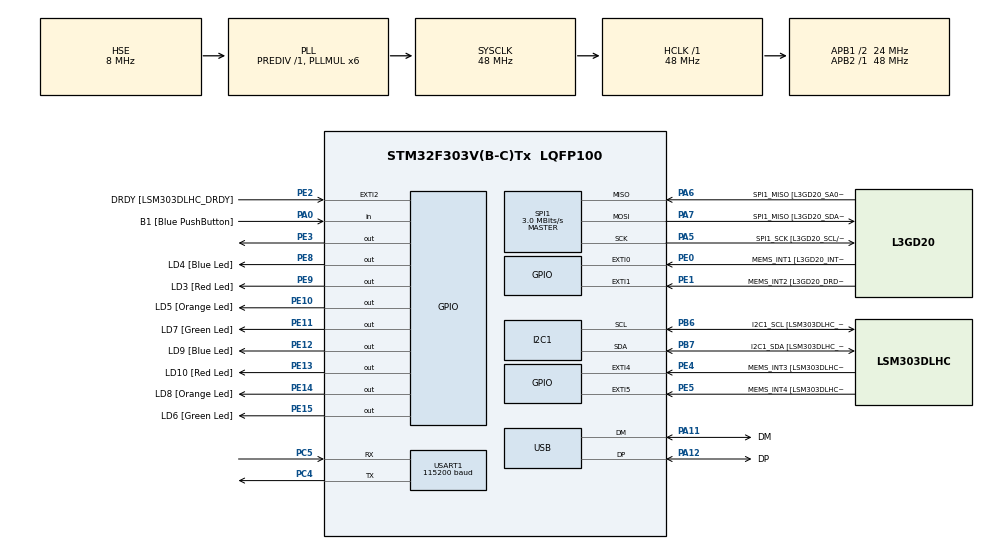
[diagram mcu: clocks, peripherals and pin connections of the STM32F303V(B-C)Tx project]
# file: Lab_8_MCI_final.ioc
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I2C1.Timing=0x2000090E
I2C1.Timing-I2C=0x2000090E
Mcu.Family=STM32F3
Mcu.Name=STM32F303V(B-C)Tx
Mcu.Package=LQFP100
NVIC.PriorityGroup=NVIC_PRIORITYGROUP_0
NVIC.SPI1_IRQn=true\:0\:0\:false\:false\:true\:true\:true\:true
PA0.GPIO_Label=B1 [Blue PushButton]
PA0.Signal=GPIO_Input
PA11.GPIO_Label=DM
PA11.Mode=Device
PA11.Signal=USB_DM
PA12.GPIO_Label=DP
PA12.Mode=Device
PA12.Signal=USB_DP
PA13.GPIO_Label=SWDIO
PA13.Mode=Serial_Wire
PA13.Signal=SYS_JTMS-SWDIO
PA14.GPIO_Label=SWCLK
PA14.Mode=Serial_Wire
PA14.Signal=SYS_JTCK-SWCLK
PA5.GPIO_Label=SPI1_SCK [L3GD20_SCL/SPC]
PA5.Mode=Full_Duplex_Master
PA5.Signal=SPI1_SCK
PA6.GPIO_Label=SPI1_MISO [L3GD20_SA0/SDO]
PA6.Mode=Full_Duplex_Master
PA6.Signal=SPI1_MISO
PA7.GPIO_Label=SPI1_MISO [L3GD20_SDA/SDI/SDO]
PA7.Mode=Full_Duplex_Master
PA7.Signal=SPI1_MOSI
PB3.GPIO_Label=SWO
PB3.Signal=SYS_JTDO-TRACESWO
PB6.GPIO_Label=I2C1_SCL [LSM303DLHC_SCL]
PB6.GPIO_Pu=GPIO_PULLUP
PB6.Mode=I2C
PB6.Signal=I2C1_SCL
PB7.GPIO_Label=I2C1_SDA [LSM303DLHC_SDA]
PB7.GPIO_Pu=GPIO_PULLUP
PB7.Mode=I2C
PB7.Signal=I2C1_SDA
PC14-OSC32_IN.GPIO_Label=OSC32_IN
PC14-OSC32_IN.Signal=RCC_OSC32_IN
PC15-OSC32_OUT.GPIO_Label=OSC32_OUT
PC15-OSC32_OUT.Signal=RCC_OSC32_OUT
PC4.Mode=Asynchronous
PC4.Signal=USART1_TX
PC5.Mode=Asynchronous
PC5.Signal=USART1_RX
PE0.GPIO_Label=MEMS_INT1 [L3GD20_INT1]
PE0.GPIO_ModeDefaultEXTI=GPIO_MODE_EVT_RISING
PE0.Signal=GPXTI0
PE1.GPIO_Label=MEMS_INT2 [L3GD20_DRDY/INT2]
PE1.GPIO_ModeDefaultEXTI=GPIO_MODE_EVT_RISING
PE1.Signal=GPXTI1
PE10.GPIO_Label=LD5 [Orange Led]
PE10.Signal=GPIO_Output
PE11.GPIO_Label=LD7 [Green Led]
PE11.Signal=GPIO_Output
PE12.GPIO_Label=LD9 [Blue Led]
PE12.Signal=GPIO_Output
PE13.GPIO_Label=LD10 [Red Led]
PE13.Signal=GPIO_Output
PE14.GPIO_Label=LD8 [Orange Led]
PE14.Signal=GPIO_Output
PE15.GPIO_Label=LD6 [Green Led]
PE15.Signal=GPIO_Output
PE2.GPIO_Label=DRDY [LSM303DLHC_DRDY]
PE2.GPIO_ModeDefaultEXTI=GPIO_MODE_EVT_RISING
PE2.Signal=GPXTI2
PE3.Signal=GPIO_Output
PE4.GPIO_Label=MEMS_INT3 [LSM303DLHC_INT1]
PE4.GPIO_ModeDefaultEXTI=GPIO_MODE_EVT_RISING
PE4.Signal=GPXTI4
PE5.GPIO_Label=MEMS_INT4 [LSM303DLHC_INT2]
PE5.GPIO_ModeDefaultEXTI=GPIO_MODE_EVT_RISING
PE5.Signal=GPXTI5
PE8.GPIO_Label=LD4 [Blue Led]
PE8.Signal=GPIO_Output
PE9.GPIO_Label=LD3 [Red Led]
PE9.Signal=GPIO_Output
PF0-OSC_IN.GPIO_Label=OSC_IN
PF0-OSC_IN.Mode=HSE-External-Clock-Source
PF0-OSC_IN.Signal=RCC_OSC_IN
PF1-OSC_OUT.GPIO_Label=OSC_OUT
PF1-OSC_OUT.Signal=RCC_OSC_OUT
ProjectManager.HeapSize=0x200
ProjectManager.StackSize=0x400
ProjectManager.TargetToolchain=CMake
RCC.AHBFreq_Value=48000000
RCC.APB1CLKDivider=RCC_HCLK_DIV2
RCC.APB1Freq_Value=24000000
RCC.APB1TimFreq_Value=48000000
RCC.APB2Freq_Value=48000000
RCC.APB2TimFreq_Value=48000000
RCC.CortexFreq_Value=48000000
RCC.HCLKFreq_Value=48000000
RCC.HSE_VALUE=8000000
RCC.HSI_VALUE=8000000
RCC.LSE_VALUE=32768
RCC.PLLMUL=RCC_PLL_MUL6
RCC.SYSCLKFreq_VALUE=48000000
RCC.SYSCLKSourceVirtual=RCC_SYSCLKSOURCE_PLLCLK
RCC.USBFreq_Value=48000000
SPI1.BaudRatePrescaler=SPI_BAUDRATEPRESCALER_16
SPI1.BaudRatePrescaler-Full_Duplex_Master=SPI_BAUDRATEPRESCALER_2
SPI1.CLKPhase=SPI_PHASE_2EDGE
SPI1.CLKPolarity=SPI_POLARITY_HIGH
SPI1.CalculateBaudRate=3.0 MBits/s
SPI1.CalculateBaudRate-Full_Duplex_Master=24.0 MBits/s
SPI1.DataSize=SPI_DATASIZE_8BIT
SPI1.Direction=SPI_DIRECTION_2LINES
SPI1.Mode=SPI_MODE_MASTER
SPI1.Mode-Full_Duplex_Master=SPI_MODE_MASTER
SPI1.VirtualType=VM_MASTER
USART1.BaudRate=115200
USART1.VirtualMode-Asynchronous=VM_ASYNC
board=STM32F3DISCOVERY

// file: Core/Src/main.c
/* USER CODE BEGIN Header */
/**
  ******************************************************************************
  * @file           : main.c
  * @brief          : Main program body
  ******************************************************************************
  * @attention
  *
  * Copyright (c) 2025 STMicroelectronics.
  * All rights reserved.
  *
  * This software is licensed under terms that can be found in the LICENSE file
  * in the root directory of this software component.
  * If no LICENSE file comes with this software, it is provided AS-IS.
  *
  ******************************************************************************
  */
/* USER CODE END Header */
#include "main.h"
#include <stdio.h>
#include <string.h>

#define CTRL_REG1      0x20
#define CTRL_REG1_VAL  0x0F  // PD=1, Xen=1, Yen=1, Zen=1 (power on + axes enabled)
#define OUT_TEMP       0x26
#define SPI_READ_CMD   0x80
#define WHO_AM_I       0x0F

#define OUT_X_L        0x28
#define OUT_X_H        0x29
#define OUT_Y_L        0x2A
#define OUT_Y_H        0x2B
#define OUT_Z_L        0x2C
#define OUT_Z_H        0x2D

I2C_HandleTypeDef hi2c1;

SPI_HandleTypeDef hspi1;

UART_HandleTypeDef huart1;

PCD_HandleTypeDef hpcd_USB_FS;

void SystemClock_Config(void);
static void MX_GPIO_Init(void);
static void MX_I2C1_Init(void);
static void MX_SPI1_Init(void);
static void MX_USART1_UART_Init(void);
static void MX_USB_PCD_Init(void);

volatile uint8_t spi_tx_in_progress = 0;
uint8_t tx_cmd;            // volatile because used in ISR sequence
uint8_t rx_val;            // volatile because written in ISR
int8_t latest_temp = 0;    // latest signed temp value
uint8_t temp_ready = 0;    // ISR -> main flag
char uart_buf[64];

#define CS_LOW()  HAL_GPIO_WritePin(GPIOE, GPIO_PIN_3, GPIO_PIN_RESET)
#define CS_HIGH() HAL_GPIO_WritePin(GPIOE, GPIO_PIN_3, GPIO_PIN_SET)
void gyro_init(void);
void start_temp_read_it(void);
#define GYRO_CS_GPIO_PORT  GPIOE
#define GYRO_CS_PIN        GPIO_PIN_3

static inline uint8_t gyro_read_cmd(uint8_t reg) {
    return (uint8_t)(0x80 | (reg & 0x3F)); // Read bit =1 ; auto-inc disabled for single
}

uint8_t read_who_am_i(void)
{
    uint8_t cmd = gyro_read_cmd(WHO_AM_I);
    uint8_t tx[2] = { cmd, 0x00 };
    uint8_t rx[2] = {0};

    HAL_GPIO_WritePin(GYRO_CS_GPIO_PORT, GYRO_CS_PIN, GPIO_PIN_RESET);
    HAL_SPI_TransmitReceive(&hspi1, tx, rx, 2, HAL_MAX_DELAY);
    HAL_GPIO_WritePin(GYRO_CS_GPIO_PORT, GYRO_CS_PIN, GPIO_PIN_SET);

    return rx[1]; // rx[0] is dummy for command, rx[1] is register value
}
static uint8_t read_who_am_i_polling(void)
{
    uint8_t cmd = gyro_read_cmd(WHO_AM_I);   // sets read bit
    uint8_t tx[2] = { cmd, 0x00 };
    uint8_t rx[2] = { 0 };

    /* CS low, transfer 2 bytes: send cmd, read reply */
    HAL_GPIO_WritePin(GYRO_CS_GPIO_PORT, GYRO_CS_PIN, GPIO_PIN_RESET);
    HAL_SPI_TransmitReceive(&hspi1, tx, rx, 2, HAL_MAX_DELAY);
    HAL_GPIO_WritePin(GYRO_CS_GPIO_PORT, GYRO_CS_PIN, GPIO_PIN_SET);

    return rx[1]; /* second byte is register value */
}
static inline uint8_t gyro_read_cmd_ai(uint8_t reg) {
    return (uint8_t)(0xC0 | (reg & 0x3F)); // 1<<7 (read) + 1<<6 (auto-increment)
}
/* Task 3: Read X,Y,Z using polling mode, convert to dps and print CSV */
void read_angular_rates_and_print(void)
{
    // Use auto-increment read of 6 bytes starting at OUT_X_L
    uint8_t cmd = gyro_read_cmd_ai(OUT_X_L);
    uint8_t tx[7]; // 1 cmd + 6 dummy
    uint8_t rx[7];
    memset(tx, 0, sizeof(tx));
    tx[0] = cmd;

    HAL_GPIO_WritePin(GYRO_CS_GPIO_PORT, GYRO_CS_PIN, GPIO_PIN_RESET);
    HAL_SPI_TransmitReceive(&hspi1, tx, rx, 7, HAL_MAX_DELAY);
    HAL_GPIO_WritePin(GYRO_CS_GPIO_PORT, GYRO_CS_PIN, GPIO_PIN_SET);

    // rx[1]..rx[6] are data (L then H per axis)
    int16_t x_raw = (int16_t)((rx[2] << 8) | rx[1]);
    int16_t y_raw = (int16_t)((rx[4] << 8) | rx[3]);
    int16_t z_raw = (int16_t)((rx[6] << 8) | rx[5]);

    float sensitivity = 0.00875f; // 8.75 mdps per LSB -> 0.00875 dps/LSB (±245 dps)
    float x_dps = x_raw * sensitivity;
    float y_dps = y_raw * sensitivity;
    float z_dps = z_raw * sensitivity;

    // Also read temperature in polling style (single byte)
    uint8_t cmdt = gyro_read_cmd(OUT_TEMP);
    uint8_t txt[2] = { cmdt, 0x00 };
    uint8_t rxt[2];
    HAL_GPIO_WritePin(GYRO_CS_GPIO_PORT, GYRO_CS_PIN, GPIO_PIN_RESET);
    HAL_SPI_TransmitReceive(&hspi1, txt, rxt, 2, HAL_MAX_DELAY);
    HAL_GPIO_WritePin(GYRO_CS_GPIO_PORT, GYRO_CS_PIN, GPIO_PIN_SET);
    int8_t temp = (int8_t)rxt[1];

    // Format: <temp>, <x_dps>, <y_dps>, <z_dps>\n
    char out[128];
    int len = snprintf(out, sizeof(out), "%d, %.2f, %.2f, %.2f\r\n", temp, x_dps, y_dps, z_dps);
    HAL_UART_Transmit(&huart1, (uint8_t*)out, len, HAL_MAX_DELAY);
}
/* helpers needed by Task 3 -------------------------------------------------*/

/* sensitivity (dps per LSB) for ±245 dps full-scale */
static const float GYRO_SENSITIVITY_DPS_PER_LSB = 0.00875f;

/* Blocking helper: read a 16-bit little-endian register pair starting at low_addr.
   Returns signed 16-bit value (OUT_L then OUT_H). */
static int16_t read_register_16(uint8_t low_addr)
{
    uint8_t cmd = gyro_read_cmd_ai(low_addr); // read + auto-inc
    uint8_t tx[7]; // will only send 1 cmd + receive 6 bytes when reading 3 axes,
                   // but for a single 16-bit read we use 1 cmd + 2 dummy
    uint8_t rx[3];
    memset(tx, 0, sizeof(tx));
    tx[0] = cmd;

    HAL_GPIO_WritePin(GYRO_CS_GPIO_PORT, GYRO_CS_PIN, GPIO_PIN_RESET);
    /* send command (1 byte) and receive 2 bytes */
    HAL_SPI_TransmitReceive(&hspi1, tx, rx, 3, HAL_MAX_DELAY);
    HAL_GPIO_WritePin(GYRO_CS_GPIO_PORT, GYRO_CS_PIN, GPIO_PIN_SET);

    /* rx[1] is first returned byte (LOW), rx[2] is HIGH if using 3-byte transfer */
    /* When using HAL_SPI_TransmitReceive with length=3: rx[0] is dummy, rx[1]=LOW, rx[2]=HIGH */
    int16_t val = (int16_t)((rx[2] << 8) | rx[1]);
    return val;
}

/* Blocking helper: read single 8-bit OUT_TEMP (signed) */
static int8_t read_temp(void)
{
    uint8_t cmd = gyro_read_cmd(OUT_TEMP);
    uint8_t tx[2] = { cmd, 0x00 };
    uint8_t rx[2] = {0};

    HAL_GPIO_WritePin(GYRO_CS_GPIO_PORT, GYRO_CS_PIN, GPIO_PIN_RESET);
    HAL_SPI_TransmitReceive(&hspi1, tx, rx, 2, HAL_MAX_DELAY);
    HAL_GPIO_WritePin(GYRO_CS_GPIO_PORT, GYRO_CS_PIN, GPIO_PIN_SET);

    return (int8_t)rx[1];
}

int main(void)
{

  /* MCU Configuration--------------------------------------------------------*/

  /* Reset of all peripherals, Initializes the Flash interface and the Systick. */
  HAL_Init();

  /* Configure the system clock */
  SystemClock_Config();

  /* Initialize all configured peripherals */
  MX_GPIO_Init();
  MX_I2C1_Init();
  MX_SPI1_Init();
  MX_USART1_UART_Init();
  MX_USB_PCD_Init();

  HAL_GPIO_WritePin(GYRO_CS_GPIO_PORT, GYRO_CS_PIN, GPIO_PIN_SET);
  gyro_init();
  // TASK 1: read WHO_AM_I and print once
    uint8_t id = read_who_am_i();
    char buf[64];
    int l = snprintf(buf, sizeof(buf), "WHO_AM_I = 0x%02X\r\n", id);
    HAL_UART_Transmit(&huart1, (uint8_t*)buf, l, HAL_MAX_DELAY);
    HAL_Delay(100);
  /* USER CODE BEGIN 2 */
const uint32_t sample_period_ms = 20; // 20 ms -> 50 Hz. Change to 100 for 10 Hz, etc.
  /* USER CODE END 2 */

  /* Infinite loop */
  /* USER CODE BEGIN WHILE */
 while (1)
{
    uint32_t ts = HAL_GetTick(); // ms timestamp

    // Read X/Y/Z in blocking mode
    int16_t x_raw = read_register_16(OUT_X_L);
    int16_t y_raw = read_register_16(OUT_Y_L);
    int16_t z_raw = read_register_16(OUT_Z_L);

    // Temperature (signed 8-bit)
    int8_t temp = read_temp();

    // Convert to dps
    float x_dps = ((float)x_raw) * GYRO_SENSITIVITY_DPS_PER_LSB;
    float y_dps = ((float)y_raw) * GYRO_SENSITIVITY_DPS_PER_LSB;
    float z_dps = ((float)z_raw) * GYRO_SENSITIVITY_DPS_PER_LSB;

    // CSV: timestamp(ms), temp, x, y, z
    int n = snprintf(uart_buf, sizeof(uart_buf),
                     "%lu, %d, %.2f, %.2f, %.2f\r\n",
                     (unsigned long)ts, (int)temp, x_dps, y_dps, z_dps);

    if (n > 0) {
        HAL_UART_Transmit(&huart1, (uint8_t*)uart_buf, n, HAL_MAX_DELAY);
        // If your VCP is on USART2, change &huart1 -> &huart2
    }

    HAL_GPIO_TogglePin(LD3_GPIO_Port, LD3_Pin); // heartbeat
    HAL_Delay(sample_period_ms);
}
}
void gyro_init(void)
{
  uint8_t tx[2];
  // write op: bit7 = 0, so just register address
  tx[0] = CTRL_REG1 & 0x3F; // ensure top bits clear (write)
  tx[1] = CTRL_REG1_VAL;

  CS_LOW();
  HAL_SPI_Transmit(&hspi1, tx, 2, HAL_MAX_DELAY); // polling is OK for init
  CS_HIGH();

  /* small delay to let device power up */
  HAL_Delay(20);
}
void start_temp_read_it(void)
{
tx_cmd = (uint8_t)(SPI_READ_CMD | (OUT_TEMP & 0x3F));

  CS_LOW();
  spi_tx_in_progress = 1;
  // send command byte, then receive in the TxCplt callback
  HAL_SPI_Transmit_IT(&hspi1, &tx_cmd, 1);
}
void HAL_SPI_TxCpltCallback(SPI_HandleTypeDef *hspi)
{
  if (hspi->Instance == SPI1) {
    /* now request 1 byte receive (device will respond on MISO while we clock) */
    HAL_SPI_Receive_IT(&hspi1, &rx_val, 1);
    /* keep CS LOW until RxCplt */
  }
}
void HAL_SPI_RxCpltCallback(SPI_HandleTypeDef *hspi)
{
  if (hspi->Instance == SPI1) {
    CS_HIGH();                  // end transaction
    spi_tx_in_progress = 0;     // ready for next read

    /* convert to signed 8-bit temperature (OUT_TEMP is two's complement) */
    latest_temp = (int8_t)rx_val;

    /* Set flag for main loop to send UART (do NOT do UART here) */
    temp_ready = 1;
  }
}

void SystemClock_Config(void)
{
  RCC_OscInitTypeDef RCC_OscInitStruct = {0};
  RCC_ClkInitTypeDef RCC_ClkInitStruct = {0};
  RCC_PeriphCLKInitTypeDef PeriphClkInit = {0};

  /** Initializes the RCC Oscillators according to the specified parameters
  * in the RCC_OscInitTypeDef structure.
  */
  RCC_OscInitStruct.OscillatorType = RCC_OSCILLATORTYPE_HSI|RCC_OSCILLATORTYPE_HSE;
  RCC_OscInitStruct.HSEState = RCC_HSE_BYPASS;
  RCC_OscInitStruct.HSEPredivValue = RCC_HSE_PREDIV_DIV1;
  RCC_OscInitStruct.HSIState = RCC_HSI_ON;
  RCC_OscInitStruct.HSICalibrationValue = RCC_HSICALIBRATION_DEFAULT;
  RCC_OscInitStruct.PLL.PLLState = RCC_PLL_ON;
  RCC_OscInitStruct.PLL.PLLSource = RCC_PLLSOURCE_HSE;
  RCC_OscInitStruct.PLL.PLLMUL = RCC_PLL_MUL6;
  if (HAL_RCC_OscConfig(&RCC_OscInitStruct) != HAL_OK)
  {
    Error_Handler();
  }

  /** Initializes the CPU, AHB and APB buses clocks
  */
  RCC_ClkInitStruct.ClockType = RCC_CLOCKTYPE_HCLK|RCC_CLOCKTYPE_SYSCLK
                              |RCC_CLOCKTYPE_PCLK1|RCC_CLOCKTYPE_PCLK2;
  RCC_ClkInitStruct.SYSCLKSource = RCC_SYSCLKSOURCE_PLLCLK;
  RCC_ClkInitStruct.AHBCLKDivider = RCC_SYSCLK_DIV1;
  RCC_ClkInitStruct.APB1CLKDivider = RCC_HCLK_DIV2;
  RCC_ClkInitStruct.APB2CLKDivider = RCC_HCLK_DIV1;

  if (HAL_RCC_ClockConfig(&RCC_ClkInitStruct, FLASH_LATENCY_1) != HAL_OK)
  {
    Error_Handler();
  }
  PeriphClkInit.PeriphClockSelection = RCC_PERIPHCLK_USB|RCC_PERIPHCLK_USART1
                              |RCC_PERIPHCLK_I2C1;
  PeriphClkInit.Usart1ClockSelection = RCC_USART1CLKSOURCE_PCLK2;
  PeriphClkInit.I2c1ClockSelection = RCC_I2C1CLKSOURCE_HSI;
  PeriphClkInit.USBClockSelection = RCC_USBCLKSOURCE_PLL;
  if (HAL_RCCEx_PeriphCLKConfig(&PeriphClkInit) != HAL_OK)
  {
    Error_Handler();
  }
}

static void MX_I2C1_Init(void)
{

  hi2c1.Instance = I2C1;
  hi2c1.Init.Timing = 0x2000090E;
  hi2c1.Init.OwnAddress1 = 0;
  hi2c1.Init.AddressingMode = I2C_ADDRESSINGMODE_7BIT;
  hi2c1.Init.DualAddressMode = I2C_DUALADDRESS_DISABLE;
  hi2c1.Init.OwnAddress2 = 0;
  hi2c1.Init.OwnAddress2Masks = I2C_OA2_NOMASK;
  hi2c1.Init.GeneralCallMode = I2C_GENERALCALL_DISABLE;
  hi2c1.Init.NoStretchMode = I2C_NOSTRETCH_DISABLE;
  if (HAL_I2C_Init(&hi2c1) != HAL_OK)
  {
    Error_Handler();
  }

  /** Configure Analogue filter
  */
  if (HAL_I2CEx_ConfigAnalogFilter(&hi2c1, I2C_ANALOGFILTER_ENABLE) != HAL_OK)
  {
    Error_Handler();
  }

  /** Configure Digital filter
  */
  if (HAL_I2CEx_ConfigDigitalFilter(&hi2c1, 0) != HAL_OK)
  {
    Error_Handler();
  }

}

static void MX_SPI1_Init(void)
{

  /* SPI1 parameter configuration*/
  hspi1.Instance = SPI1;
  hspi1.Init.Mode = SPI_MODE_MASTER;
  hspi1.Init.Direction = SPI_DIRECTION_2LINES;
  hspi1.Init.DataSize = SPI_DATASIZE_8BIT;
  hspi1.Init.CLKPolarity = SPI_POLARITY_HIGH;
  hspi1.Init.CLKPhase = SPI_PHASE_2EDGE;
  hspi1.Init.NSS = SPI_NSS_SOFT;
  hspi1.Init.BaudRatePrescaler = SPI_BAUDRATEPRESCALER_16;
  hspi1.Init.FirstBit = SPI_FIRSTBIT_MSB;
  hspi1.Init.TIMode = SPI_TIMODE_DISABLE;
  hspi1.Init.CRCCalculation = SPI_CRCCALCULATION_DISABLE;
  hspi1.Init.CRCPolynomial = 7;
  hspi1.Init.CRCLength = SPI_CRC_LENGTH_DATASIZE;
  hspi1.Init.NSSPMode = SPI_NSS_PULSE_DISABLE;
  if (HAL_SPI_Init(&hspi1) != HAL_OK)
  {
    Error_Handler();
  }

}

static void MX_USART1_UART_Init(void)
{

  huart1.Instance = USART1;
  huart1.Init.BaudRate = 115200;
  huart1.Init.WordLength = UART_WORDLENGTH_8B;
  huart1.Init.StopBits = UART_STOPBITS_1;
  huart1.Init.Parity = UART_PARITY_NONE;
  huart1.Init.Mode = UART_MODE_TX_RX;
  huart1.Init.HwFlowCtl = UART_HWCONTROL_NONE;
  huart1.Init.OverSampling = UART_OVERSAMPLING_16;
  huart1.Init.OneBitSampling = UART_ONE_BIT_SAMPLE_DISABLE;
  huart1.AdvancedInit.AdvFeatureInit = UART_ADVFEATURE_NO_INIT;
  if (HAL_UART_Init(&huart1) != HAL_OK)
  {
    Error_Handler();
  }

}

static void MX_USB_PCD_Init(void)
{

  hpcd_USB_FS.Instance = USB;
  hpcd_USB_FS.Init.dev_endpoints = 8;
  hpcd_USB_FS.Init.speed = PCD_SPEED_FULL;
  hpcd_USB_FS.Init.phy_itface = PCD_PHY_EMBEDDED;
  hpcd_USB_FS.Init.low_power_enable = DISABLE;
  hpcd_USB_FS.Init.battery_charging_enable = DISABLE;
  if (HAL_PCD_Init(&hpcd_USB_FS) != HAL_OK)
  {
    Error_Handler();
  }

}

static void MX_GPIO_Init(void)
{
  GPIO_InitTypeDef GPIO_InitStruct = {0};

  /* GPIO Ports Clock Enable */
  __HAL_RCC_GPIOE_CLK_ENABLE();
  __HAL_RCC_GPIOC_CLK_ENABLE();
  __HAL_RCC_GPIOF_CLK_ENABLE();
  __HAL_RCC_GPIOA_CLK_ENABLE();
  __HAL_RCC_GPIOB_CLK_ENABLE();

  /*Configure GPIO pin Output Level */
  HAL_GPIO_WritePin(GPIOE, GPIO_PIN_3|LD4_Pin|LD3_Pin|LD5_Pin
                          |LD7_Pin|LD9_Pin|LD10_Pin|LD8_Pin
                          |LD6_Pin, GPIO_PIN_RESET);

  /*Configure GPIO pins : DRDY_Pin MEMS_INT3_Pin MEMS_INT4_Pin MEMS_INT1_Pin
                           MEMS_INT2_Pin */
  GPIO_InitStruct.Pin = DRDY_Pin|MEMS_INT3_Pin|MEMS_INT4_Pin|MEMS_INT1_Pin
                          |MEMS_INT2_Pin;
  GPIO_InitStruct.Mode = GPIO_MODE_EVT_RISING;
  GPIO_InitStruct.Pull = GPIO_NOPULL;
  HAL_GPIO_Init(GPIOE, &GPIO_InitStruct);

  /*Configure GPIO pins : PE3 LD4_Pin LD3_Pin LD5_Pin
                           LD7_Pin LD9_Pin LD10_Pin LD8_Pin
                           LD6_Pin */
  GPIO_InitStruct.Pin = GPIO_PIN_3|LD4_Pin|LD3_Pin|LD5_Pin
                          |LD7_Pin|LD9_Pin|LD10_Pin|LD8_Pin
                          |LD6_Pin;
  GPIO_InitStruct.Mode = GPIO_MODE_OUTPUT_PP;
  GPIO_InitStruct.Pull = GPIO_NOPULL;
  GPIO_InitStruct.Speed = GPIO_SPEED_FREQ_LOW;
  HAL_GPIO_Init(GPIOE, &GPIO_InitStruct);

  /*Configure GPIO pin : B1_Pin */
  GPIO_InitStruct.Pin = B1_Pin;
  GPIO_InitStruct.Mode = GPIO_MODE_INPUT;
  GPIO_InitStruct.Pull = GPIO_NOPULL;
  HAL_GPIO_Init(B1_GPIO_Port, &GPIO_InitStruct);

}

void Error_Handler(void)
{
  __disable_irq();
  while (1)
  {
  }
}
